# ESP32-S3 register map
Vendor: ESPRESSIF SYSTEMS (SHANGHAI) CO., LTD.; Series: ESP32 S-Series; File version: 22
CPU: Xtensa LX7 r0p0, little endian, no MPU, FPU, 0 interrupt priority bits
Address unit: 32 bits
Registers are 32-bit, read-write, reset 0x0 unless marked. A register's access mark holds for its fields unless they carry their own. Offsets are from the block's base; [hi:lo] are bit positions; {n}, {i} and the like mark numbered series.

## RTC_CNTL — Real-Time Clock Control
Base 0x60008000
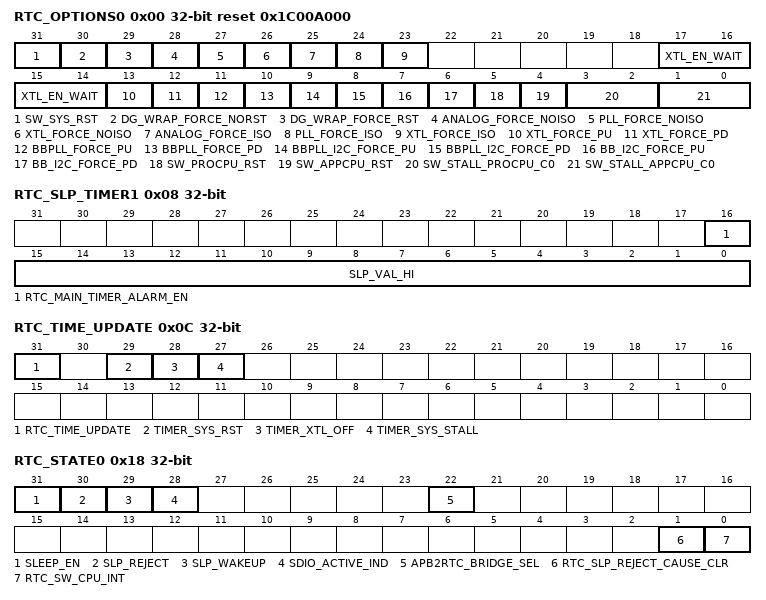
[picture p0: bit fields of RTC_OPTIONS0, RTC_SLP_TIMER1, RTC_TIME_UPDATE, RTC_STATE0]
0x00 RTC_OPTIONS0 access per field reset 0x1C00A000 — RTC common configure register
  [31] SW_SYS_RST wo — SW system reset
  [30] DG_WRAP_FORCE_NORST rw — digital core force no reset in deep sleep
  [29] DG_WRAP_FORCE_RST rw — digital wrap force reset in deep sleep
  [28] ANALOG_FORCE_NOISO rw — No public
  [27] PLL_FORCE_NOISO rw — No public
  [26] XTL_FORCE_NOISO rw — No public
  [25] ANALOG_FORCE_ISO rw — No public
  [24] PLL_FORCE_ISO rw — No public
  [23] XTL_FORCE_ISO rw — No public
  [17:14] XTL_EN_WAIT rw — wait bias_sleep and current source wakeup
  [13] XTL_FORCE_PU rw — crystall force power up
  [12] XTL_FORCE_PD rw — crystall force power down
  [11] BBPLL_FORCE_PU rw — BB_PLL force power up
  [10] BBPLL_FORCE_PD rw — BB_PLL force power down
  [9] BBPLL_I2C_FORCE_PU rw — BB_PLL_I2C force power up
  [8] BBPLL_I2C_FORCE_PD rw — BB_PLL _I2C force power down
  [7] BB_I2C_FORCE_PU rw — BB_I2C force power up
  [6] BB_I2C_FORCE_PD rw — BB_I2C force power down
  [5] SW_PROCPU_RST wo — PRO CPU SW reset
  [4] SW_APPCPU_RST wo — APP CPU SW reset
  [3:2] SW_STALL_PROCPU_C0 rw — {reg_sw_stall_procpu_c1[5:0], reg_sw_stall_procpu_c0[1:0]} == 0x86 will stall PRO CPU
  [1:0] SW_STALL_APPCPU_C0 rw — {reg_sw_stall_appcpu_c1[5:0], reg_sw_stall_appcpu_c0[1:0]} == 0x86 will stall APP CPU
0x04 RTC_SLP_TIMER0 — configure min sleep time
  [31:0] SLP_VAL_LO — RTC sleep timer low 32 bits
0x08 RTC_SLP_TIMER1 access per field — configure sleep time hi
  [16] RTC_MAIN_TIMER_ALARM_EN wo — timer alarm enable bit
  [15:0] SLP_VAL_HI rw — RTC sleep timer high 16 bits
0x0C RTC_TIME_UPDATE access per field — update rtc main timer
  [31] RTC_TIME_UPDATE wo — Set 1: to update register with RTC timer
  [29] TIMER_SYS_RST rw — enable to record system reset time
  [28] TIMER_XTL_OFF rw — Enable to record 40M XTAL OFF time
  [27] TIMER_SYS_STALL rw — Enable to record system stall time
0x10 RTC_TIME_LOW0 ro — read rtc_main timer low bits
  [31:0] RTC_TIMER_VALUE0_LOW — RTC timer low 32 bits
0x14 RTC_TIME_HIGH0 ro — read rtc_main timer high bits
  [15:0] RTC_TIMER_VALUE0_HIGH — RTC timer high 16 bits
0x18 RTC_STATE0 access per field — configure chip sleep
  [31] SLEEP_EN rw — sleep enable bit
  [30] SLP_REJECT rw — leep reject bit
  [29] SLP_WAKEUP rw — leep wakeup bit
  [28] SDIO_ACTIVE_IND ro — SDIO active indication
  [22] APB2RTC_BRIDGE_SEL rw — 1: APB to RTC using bridge, 0: APB to RTC using sync
  [1] RTC_SLP_REJECT_CAUSE_CLR wo — clear rtc sleep reject cause
  [0] RTC_SW_CPU_INT wo — rtc software interrupt to main cpu
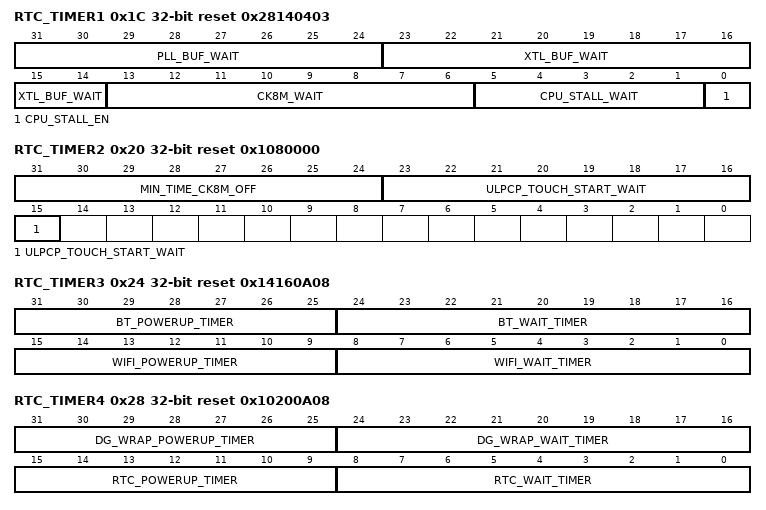
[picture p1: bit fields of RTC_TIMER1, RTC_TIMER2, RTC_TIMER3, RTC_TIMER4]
0x1C RTC_TIMER1 reset 0x28140403 — rtc state wait time
  [31:24] PLL_BUF_WAIT — PLL wait cycles in slow_clk_rtc
  [23:14] XTL_BUF_WAIT — XTAL wait cycles in slow_clk_rtc
  [13:6] CK8M_WAIT — CK8M wait cycles in slow_clk_rtc
  [5:1] CPU_STALL_WAIT — CPU stall wait cycles in fast_clk_rtc
  [0] CPU_STALL_EN — CPU stall enable bit
0x20 RTC_TIMER2 reset 0x1080000 — rtc monitor state delay time
  [31:24] MIN_TIME_CK8M_OFF — minimal cycles in slow_clk_rtc for CK8M in power down state
  [23:15] ULPCP_TOUCH_START_WAIT — wait cycles in slow_clk_rtc before ULP-coprocessor / touch controller start to work
0x24 RTC_TIMER3 reset 0x14160A08 — No public
  [31:25] BT_POWERUP_TIMER — No public
  [24:16] BT_WAIT_TIMER — No public
  [15:9] WIFI_POWERUP_TIMER — No public
  [8:0] WIFI_WAIT_TIMER — No public
0x28 RTC_TIMER4 reset 0x10200A08 — No public
  [31:25] DG_WRAP_POWERUP_TIMER — No public
  [24:16] DG_WRAP_WAIT_TIMER — No public
  [15:9] RTC_POWERUP_TIMER — No public
  [8:0] RTC_WAIT_TIMER — No public
0x2C RTC_TIMER5 reset 0x8000 — configure min sleep time
  [15:8] MIN_SLP_VAL — minimal sleep cycles in slow_clk_rtc
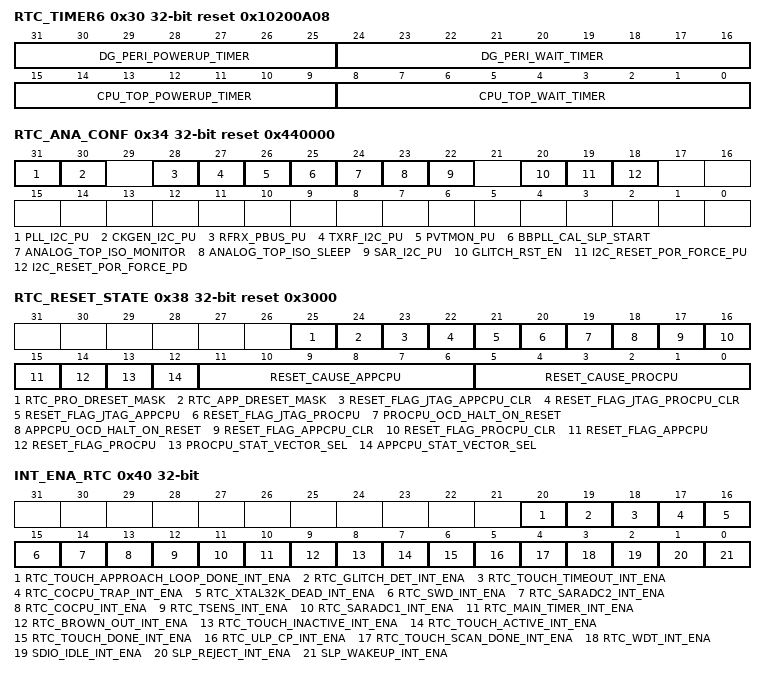
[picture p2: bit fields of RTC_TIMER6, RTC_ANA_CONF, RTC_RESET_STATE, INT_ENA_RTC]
0x30 RTC_TIMER6 reset 0x10200A08 — No public
  [31:25] DG_PERI_POWERUP_TIMER — No public
  [24:16] DG_PERI_WAIT_TIMER — No public
  [15:9] CPU_TOP_POWERUP_TIMER — No public
  [8:0] CPU_TOP_WAIT_TIMER — No public
0x34 RTC_ANA_CONF reset 0x440000 — analog configure register
  [31] PLL_I2C_PU — power on pll i2c
  [30] CKGEN_I2C_PU — 1: CKGEN_I2C power up, otherwise power down
  [28] RFRX_PBUS_PU — 1: RFRX_PBUS power up, otherwise power down
  [27] TXRF_I2C_PU — 1: TXRF_I2C power up, otherwise power down
  [26] PVTMON_PU — 1: PVTMON power up, otherwise power down
  [25] BBPLL_CAL_SLP_START — start BBPLL calibration during sleep
  [24] ANALOG_TOP_ISO_MONITOR — PLLA force power up
  [23] ANALOG_TOP_ISO_SLEEP — PLLA force power down
  [22] SAR_I2C_PU — PLLA force power up
  [20] GLITCH_RST_EN — enable clk glitch
  [19] I2C_RESET_POR_FORCE_PU — force on I2C_RESET_POR
  [18] I2C_RESET_POR_FORCE_PD — force down I2C_RESET_POR
0x38 RTC_RESET_STATE access per field reset 0x3000 — get reset state
  [25] RTC_PRO_DRESET_MASK rw — bypass cpu0 dreset
  [24] RTC_APP_DRESET_MASK rw — bypass cpu1 dreset
  [23] RESET_FLAG_JTAG_APPCPU_CLR wo — clear jtag reset flag
  [22] RESET_FLAG_JTAG_PROCPU_CLR wo — clear jtag reset flag
  [21] RESET_FLAG_JTAG_APPCPU ro — jtag reset flag
  [20] RESET_FLAG_JTAG_PROCPU ro — jtag reset flag
  [19] PROCPU_OCD_HALT_ON_RESET rw
  [18] APPCPU_OCD_HALT_ON_RESET rw
  [17] RESET_FLAG_APPCPU_CLR wo — clear APP CPU reset flag
  [16] RESET_FLAG_PROCPU_CLR wo — clear PRO CPU reset_flag
  [15] RESET_FLAG_APPCPU ro — APP CPU reset flag
  [14] RESET_FLAG_PROCPU ro — PRO CPU reset_flag
  [13] PROCPU_STAT_VECTOR_SEL rw — PRO CPU state vector sel
  [12] APPCPU_STAT_VECTOR_SEL rw — APP CPU state vector sel
  [11:6] RESET_CAUSE_APPCPU ro — reset cause of APP CPU
  [5:0] RESET_CAUSE_PROCPU ro — reset cause of PRO CPU
0x3C RTC_WAKEUP_STATE reset 0x60000 — configure wakeup state
  [31:15] RTC_WAKEUP_ENA — wakeup enable bitmap
0x40 INT_ENA_RTC — configure rtc interrupt register
  [20] RTC_TOUCH_APPROACH_LOOP_DONE_INT_ENA — touch approach mode loop interrupt
  [19] RTC_GLITCH_DET_INT_ENA — enbale gitch det interrupt
  [18] RTC_TOUCH_TIMEOUT_INT_ENA — enable touch timeout interrupt
  [17] RTC_COCPU_TRAP_INT_ENA — enable cocpu trap interrupt
  [16] RTC_XTAL32K_DEAD_INT_ENA — enable xtal32k_dead interrupt
  [15] RTC_SWD_INT_ENA — enable super watch dog interrupt
  [14] RTC_SARADC2_INT_ENA — enable saradc2 interrupt
  [13] RTC_COCPU_INT_ENA — enable riscV cocpu interrupt
  [12] RTC_TSENS_INT_ENA — enable tsens interrupt
  [11] RTC_SARADC1_INT_ENA — enable saradc1 interrupt
  [10] RTC_MAIN_TIMER_INT_ENA — enable RTC main timer interrupt
  [9] RTC_BROWN_OUT_INT_ENA — enable brown out interrupt
  [8] RTC_TOUCH_INACTIVE_INT_ENA — enable touch inactive interrupt
  [7] RTC_TOUCH_ACTIVE_INT_ENA — enable touch active interrupt
  [6] RTC_TOUCH_DONE_INT_ENA — enable touch done interrupt
  [5] RTC_ULP_CP_INT_ENA — enable ULP-coprocessor interrupt
  [4] RTC_TOUCH_SCAN_DONE_INT_ENA — enable touch scan done interrupt
  [3] RTC_WDT_INT_ENA — enable RTC WDT interrupt
  [2] SDIO_IDLE_INT_ENA — enable SDIO idle interrupt
  [1] SLP_REJECT_INT_ENA — enable sleep reject interrupt
  [0] SLP_WAKEUP_INT_ENA — enable sleep wakeup interrupt
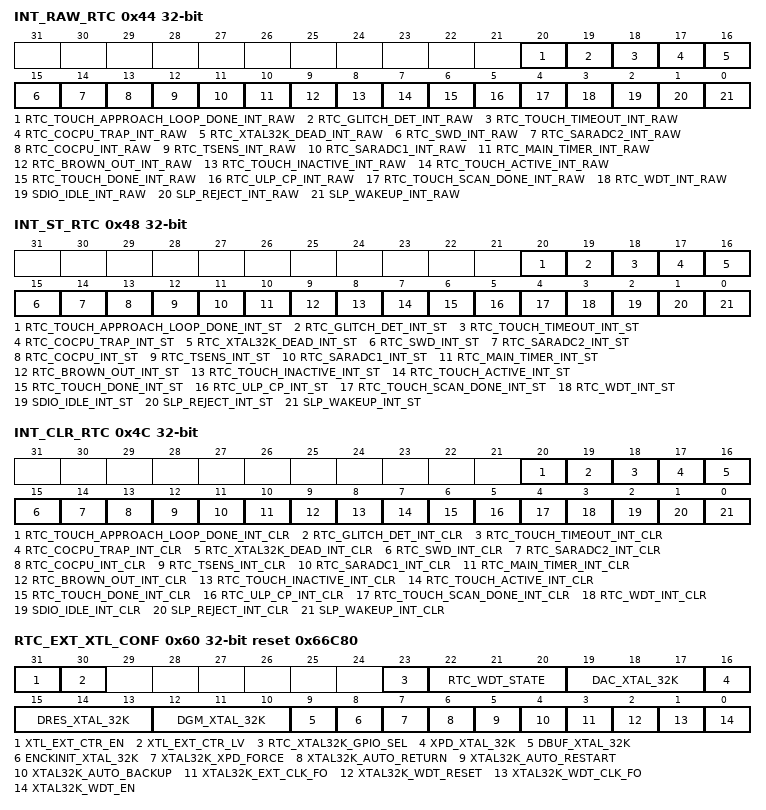
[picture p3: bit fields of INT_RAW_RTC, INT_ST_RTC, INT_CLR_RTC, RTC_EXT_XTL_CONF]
0x44 INT_RAW_RTC access per field — rtc interrupt register
  [20] RTC_TOUCH_APPROACH_LOOP_DONE_INT_RAW rw — touch approach mode loop interrupt raw
  [19] RTC_GLITCH_DET_INT_RAW ro — glitch_det_interrupt_raw
  [18] RTC_TOUCH_TIMEOUT_INT_RAW ro — touch timeout interrupt raw
  [17] RTC_COCPU_TRAP_INT_RAW ro — cocpu trap interrupt raw
  [16] RTC_XTAL32K_DEAD_INT_RAW ro — xtal32k dead detection interrupt raw
  [15] RTC_SWD_INT_RAW ro — super watch dog interrupt raw
  [14] RTC_SARADC2_INT_RAW ro — saradc2 interrupt raw
  [13] RTC_COCPU_INT_RAW ro — riscV cocpu interrupt raw
  [12] RTC_TSENS_INT_RAW ro — tsens interrupt raw
  [11] RTC_SARADC1_INT_RAW ro — saradc1 interrupt raw
  [10] RTC_MAIN_TIMER_INT_RAW ro — RTC main timer interrupt raw
  [9] RTC_BROWN_OUT_INT_RAW ro — brown out interrupt raw
  [8] RTC_TOUCH_INACTIVE_INT_RAW ro — touch inactive interrupt raw
  [7] RTC_TOUCH_ACTIVE_INT_RAW ro — touch active interrupt raw
  [6] RTC_TOUCH_DONE_INT_RAW ro — touch interrupt raw
  [5] RTC_ULP_CP_INT_RAW ro — ULP-coprocessor interrupt raw
  [4] RTC_TOUCH_SCAN_DONE_INT_RAW ro — enable touch scan done interrupt raw
  [3] RTC_WDT_INT_RAW ro — RTC WDT interrupt raw
  [2] SDIO_IDLE_INT_RAW ro — SDIO idle interrupt raw
  [1] SLP_REJECT_INT_RAW ro — sleep reject interrupt raw
  [0] SLP_WAKEUP_INT_RAW ro — sleep wakeup interrupt raw
0x48 INT_ST_RTC ro — rtc interrupt register
  [20] RTC_TOUCH_APPROACH_LOOP_DONE_INT_ST — touch approach mode loop interrupt state
  [19] RTC_GLITCH_DET_INT_ST — glitch_det_interrupt state
  [18] RTC_TOUCH_TIMEOUT_INT_ST — Touch timeout interrupt state
  [17] RTC_COCPU_TRAP_INT_ST — cocpu trap interrupt state
  [16] RTC_XTAL32K_DEAD_INT_ST — xtal32k dead detection interrupt state
  [15] RTC_SWD_INT_ST — super watch dog interrupt state
  [14] RTC_SARADC2_INT_ST — saradc2 interrupt state
  [13] RTC_COCPU_INT_ST — riscV cocpu interrupt state
  [12] RTC_TSENS_INT_ST — tsens interrupt state
  [11] RTC_SARADC1_INT_ST — saradc1 interrupt state
  [10] RTC_MAIN_TIMER_INT_ST — RTC main timer interrupt state
  [9] RTC_BROWN_OUT_INT_ST — brown out interrupt state
  [8] RTC_TOUCH_INACTIVE_INT_ST — touch inactive interrupt state
  [7] RTC_TOUCH_ACTIVE_INT_ST — touch active interrupt state
  [6] RTC_TOUCH_DONE_INT_ST — touch done interrupt state
  [5] RTC_ULP_CP_INT_ST — ULP-coprocessor interrupt state
  [4] RTC_TOUCH_SCAN_DONE_INT_ST — enable touch scan done interrupt raw
  [3] RTC_WDT_INT_ST — RTC WDT interrupt state
  [2] SDIO_IDLE_INT_ST — SDIO idle interrupt state
  [1] SLP_REJECT_INT_ST — sleep reject interrupt state
  [0] SLP_WAKEUP_INT_ST — sleep wakeup interrupt state
0x4C INT_CLR_RTC wo — rtc interrupt register
  [20] RTC_TOUCH_APPROACH_LOOP_DONE_INT_CLR — cleartouch approach mode loop interrupt state
  [19] RTC_GLITCH_DET_INT_CLR — Clear glitch det interrupt state
  [18] RTC_TOUCH_TIMEOUT_INT_CLR — Clear touch timeout interrupt state
  [17] RTC_COCPU_TRAP_INT_CLR — Clear cocpu trap interrupt state
  [16] RTC_XTAL32K_DEAD_INT_CLR — Clear RTC WDT interrupt state
  [15] RTC_SWD_INT_CLR — Clear super watch dog interrupt state
  [14] RTC_SARADC2_INT_CLR — Clear saradc2 interrupt state
  [13] RTC_COCPU_INT_CLR — Clear riscV cocpu interrupt state
  [12] RTC_TSENS_INT_CLR — Clear tsens interrupt state
  [11] RTC_SARADC1_INT_CLR — Clear saradc1 interrupt state
  [10] RTC_MAIN_TIMER_INT_CLR — Clear RTC main timer interrupt state
  [9] RTC_BROWN_OUT_INT_CLR — Clear brown out interrupt state
  [8] RTC_TOUCH_INACTIVE_INT_CLR — Clear touch inactive interrupt state
  [7] RTC_TOUCH_ACTIVE_INT_CLR — Clear touch active interrupt state
  [6] RTC_TOUCH_DONE_INT_CLR — Clear touch done interrupt state
  [5] RTC_ULP_CP_INT_CLR — Clear ULP-coprocessor interrupt state
  [4] RTC_TOUCH_SCAN_DONE_INT_CLR — clear touch scan done interrupt raw
  [3] RTC_WDT_INT_CLR — Clear RTC WDT interrupt state
  [2] SDIO_IDLE_INT_CLR — Clear SDIO idle interrupt state
  [1] SLP_REJECT_INT_CLR — Clear sleep reject interrupt state
  [0] SLP_WAKEUP_INT_CLR — Clear sleep wakeup interrupt state
{0x50+4i} RTC_STORE{i} (i=0..3) — Reserved register
  [31:0] RTC_SCRATCH{i}
0x60 RTC_EXT_XTL_CONF access per field reset 0x66C80 — Reserved register
  [31] XTL_EXT_CTR_EN rw — Reserved register
  [30] XTL_EXT_CTR_LV rw — 0: power down XTAL at high level, 1: power down XTAL at low level
  [23] RTC_XTAL32K_GPIO_SEL rw — XTAL_32K sel. 0: external XTAL_32K, 1: CLK from RTC pad X32P_C
  [22:20] RTC_WDT_STATE ro — state of 32k_wdt
  [19:17] DAC_XTAL_32K rw
  [16] XPD_XTAL_32K rw
  [15:13] DRES_XTAL_32K rw
  [12:10] DGM_XTAL_32K rw — xtal_32k gm control
  [9] DBUF_XTAL_32K rw — 0: single-end buffer 1: differential buffer
  [8] ENCKINIT_XTAL_32K rw — apply an internal clock to help xtal 32k to start
  [7] XTAL32K_XPD_FORCE rw — Xtal 32k xpd control by sw or fsm
  [6] XTAL32K_AUTO_RETURN rw — xtal 32k switch back xtal when xtal is restarted
  [5] XTAL32K_AUTO_RESTART rw — xtal 32k restart xtal when xtal is dead
  [4] XTAL32K_AUTO_BACKUP rw — xtal 32k switch to back up clock when xtal is dead
  [3] XTAL32K_EXT_CLK_FO rw — xtal 32k external xtal clock force on
  [2] XTAL32K_WDT_RESET rw — xtal 32k watch dog sw reset
  [1] XTAL32K_WDT_CLK_FO rw — xtal 32k watch dog clock force on
  [0] XTAL32K_WDT_EN rw — xtal 32k watch dog enable
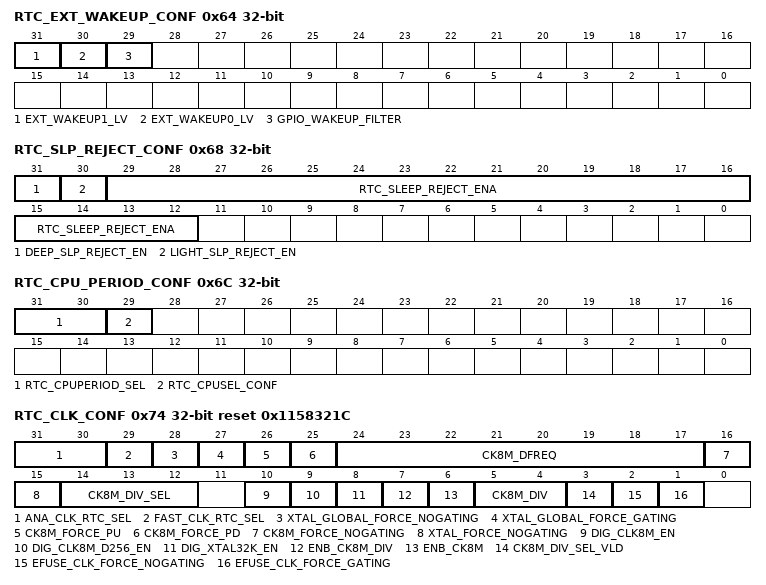
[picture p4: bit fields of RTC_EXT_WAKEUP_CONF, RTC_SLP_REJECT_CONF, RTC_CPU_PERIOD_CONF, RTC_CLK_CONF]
0x64 RTC_EXT_WAKEUP_CONF — ext wakeup configure
  [31] EXT_WAKEUP1_LV — 0: external wakeup at low level, 1: external wakeup at high level
  [30] EXT_WAKEUP0_LV — 0: external wakeup at low level, 1: external wakeup at high level
  [29] GPIO_WAKEUP_FILTER — enable filter for gpio wakeup event
0x68 RTC_SLP_REJECT_CONF — reject sleep register
  [31] DEEP_SLP_REJECT_EN — enable reject for deep sleep
  [30] LIGHT_SLP_REJECT_EN — enable reject for light sleep
  [29:12] RTC_SLEEP_REJECT_ENA — sleep reject enable
0x6C RTC_CPU_PERIOD_CONF — conigure cpu freq
  [31:30] RTC_CPUPERIOD_SEL — conigure cpu freq
  [29] RTC_CPUSEL_CONF — CPU sel option
0x70 RTC_SDIO_ACT_CONF — No public
  [31:22] SDIO_ACT_DNUM
0x74 RTC_CLK_CONF reset 0x1158321C — configure clock register
  [31:30] ANA_CLK_RTC_SEL — select slow clock
  [29] FAST_CLK_RTC_SEL — fast_clk_rtc sel. 0: XTAL div 4, 1: CK8M
  [28] XTAL_GLOBAL_FORCE_NOGATING — force global xtal no gating
  [27] XTAL_GLOBAL_FORCE_GATING — force global xtal gating
  [26] CK8M_FORCE_PU — CK8M force power up
  [25] CK8M_FORCE_PD — CK8M force power down
  [24:17] CK8M_DFREQ
  [16] CK8M_FORCE_NOGATING — CK8M force no gating during sleep
  [15] XTAL_FORCE_NOGATING — XTAL force no gating during sleep
  [14:12] CK8M_DIV_SEL — divider = reg_ck8m_div_sel + 1
  [10] DIG_CLK8M_EN — enable CK8M for digital core (no relationship with RTC core)
  [9] DIG_CLK8M_D256_EN — enable CK8M_D256_OUT for digital core (no relationship with RTC core)
  [8] DIG_XTAL32K_EN — enable CK_XTAL_32K for digital core (no relationship with RTC core)
  [7] ENB_CK8M_DIV — 1: CK8M_D256_OUT is actually CK8M, 0: CK8M_D256_OUT is CK8M divided by 256
  [6] ENB_CK8M — disable CK8M and CK8M_D256_OUT
  [5:4] CK8M_DIV — CK8M_D256_OUT divider. 00: div128, 01: div256, 10: div512, 11: div1024.
  [3] CK8M_DIV_SEL_VLD — used to sync reg_ck8m_div_sel bus. Clear vld before set reg_ck8m_div_sel, then set vld to actually switch the clk
  [2] EFUSE_CLK_FORCE_NOGATING — force efuse clk nogating
  [1] EFUSE_CLK_FORCE_GATING — force efuse clk gating
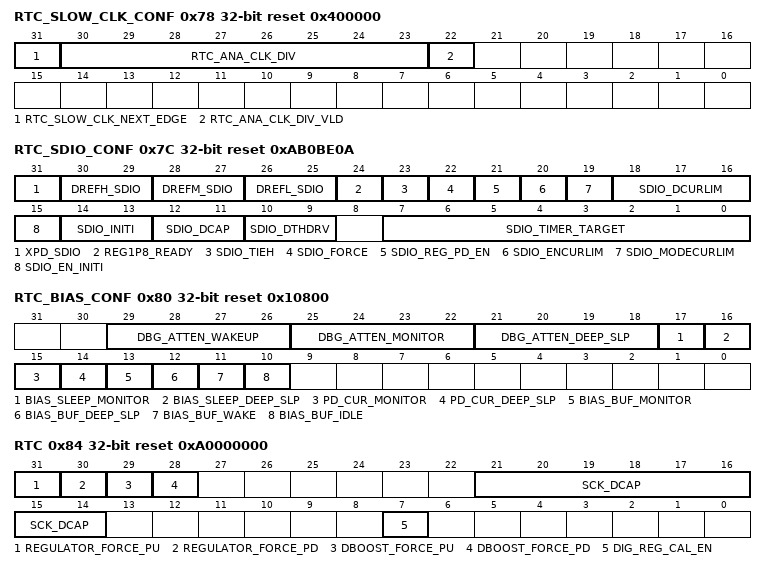
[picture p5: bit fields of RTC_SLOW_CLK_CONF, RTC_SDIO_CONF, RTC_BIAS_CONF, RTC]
0x78 RTC_SLOW_CLK_CONF reset 0x400000 — configure slow clk
  [31] RTC_SLOW_CLK_NEXT_EDGE — No public
  [30:23] RTC_ANA_CLK_DIV — rtc clk div
  [22] RTC_ANA_CLK_DIV_VLD — used to sync div bus. clear vld before set reg_rtc_ana_clk_div, then set vld to actually switch the clk
0x7C RTC_SDIO_CONF access per field reset 0xAB0BE0A — configure flash power
  [31] XPD_SDIO rw — power on flash regulator
  [30:29] DREFH_SDIO rw — SW option for DREFH_SDIO. Only active when reg_sdio_force = 1
  [28:27] DREFM_SDIO rw — SW option for DREFM_SDIO. Only active when reg_sdio_force = 1
  [26:25] DREFL_SDIO rw — SW option for DREFL_SDIO. Only active when reg_sdio_force = 1
  [24] REG1P8_READY ro — read only register for REG1P8_READY
  [23] SDIO_TIEH rw — SW option for SDIO_TIEH. Only active when reg_sdio_force = 1
  [22] SDIO_FORCE rw — 1: use SW option to control SDIO_REG, 0: use state machine
  [21] SDIO_REG_PD_EN rw — power down SDIO_REG in sleep. Only active when reg_sdio_force = 0
  [20] SDIO_ENCURLIM rw — enable current limit
  [19] SDIO_MODECURLIM rw — select current limit mode
  [18:16] SDIO_DCURLIM rw — tune current limit threshold when tieh = 0. About 800mA/(8+d)
  [15] SDIO_EN_INITI rw — 0 to set init[1:0]=0
  [14:13] SDIO_INITI rw — add resistor from ldo output to ground. 0: no res, 1: 6k,2:4k,3:2k
  [12:11] SDIO_DCAP rw — ability to prevent LDO from overshoot
  [10:9] SDIO_DTHDRV rw — Tieh = 1 mode drive ability. Initially set to 0 to limit charge current, set to 3 after several us.
  [7:0] SDIO_TIMER_TARGET rw — timer count to apply reg_sdio_dcap after sdio power on
0x80 RTC_BIAS_CONF reset 0x10800 — No public
  [29:26] DBG_ATTEN_WAKEUP — No public
  [25:22] DBG_ATTEN_MONITOR — DBG_ATTEN when rtc in monitor state
  [21:18] DBG_ATTEN_DEEP_SLP — DBG_ATTEN when rtc in sleep state
  [17] BIAS_SLEEP_MONITOR — bias_sleep when rtc in monitor state
  [16] BIAS_SLEEP_DEEP_SLP — bias_sleep when rtc in sleep_state
  [15] PD_CUR_MONITOR — xpd cur when rtc in monitor state
  [14] PD_CUR_DEEP_SLP — xpd cur when rtc in sleep_state
  [13] BIAS_BUF_MONITOR — No public
  [12] BIAS_BUF_DEEP_SLP — No public
  [11] BIAS_BUF_WAKE — No public
  [10] BIAS_BUF_IDLE — No public
0x84 RTC reset 0xA0000000 — configure rtc regulator
  [31] REGULATOR_FORCE_PU — RTC_REG force power on (for RTC_REG power down means decrease the voltage to 0.8v or lower )
  [30] REGULATOR_FORCE_PD — RTC_REG force power down (for RTC_REG power down means decrease the voltage to 0.8v or lower )
  [29] DBOOST_FORCE_PU — RTC_DBOOST force power up
  [28] DBOOST_FORCE_PD — RTC_DBOOST force power down
  [21:14] SCK_DCAP
  [7] DIG_REG_CAL_EN — enable dig regulator cali
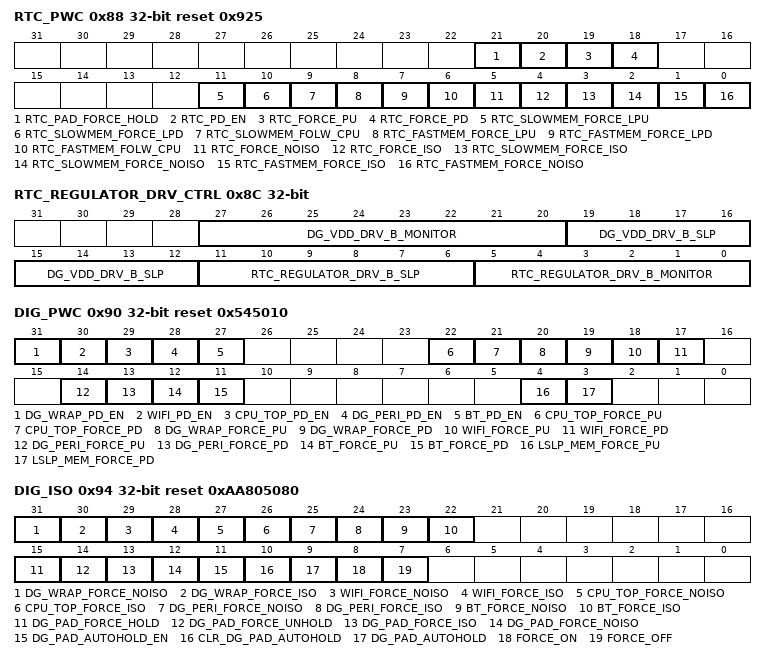
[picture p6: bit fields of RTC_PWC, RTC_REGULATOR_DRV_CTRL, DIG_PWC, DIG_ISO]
0x88 RTC_PWC reset 0x925 — configure rtc power
  [21] RTC_PAD_FORCE_HOLD
  [20] RTC_PD_EN — enable power down rtc_peri in sleep
  [19] RTC_FORCE_PU — rtc_peri force power up
  [18] RTC_FORCE_PD — rtc_peri force power down
  [11] RTC_SLOWMEM_FORCE_LPU — RTC memory force no PD
  [10] RTC_SLOWMEM_FORCE_LPD — RTC memory force PD
  [9] RTC_SLOWMEM_FOLW_CPU — 1: RTC memory PD following CPU, 0: RTC memory PD following RTC state machine
  [8] RTC_FASTMEM_FORCE_LPU — Fast RTC memory force no PD
  [7] RTC_FASTMEM_FORCE_LPD — Fast RTC memory force PD
  [6] RTC_FASTMEM_FOLW_CPU — 1: Fast RTC memory PD following CPU, 0: fast RTC memory PD following RTC state machine
  [5] RTC_FORCE_NOISO — rtc_peri force no ISO
  [4] RTC_FORCE_ISO — rtc_peri force ISO
  [3] RTC_SLOWMEM_FORCE_ISO — RTC memory force ISO
  [2] RTC_SLOWMEM_FORCE_NOISO — RTC memory force no ISO
  [1] RTC_FASTMEM_FORCE_ISO — Fast RTC memory force ISO
  [0] RTC_FASTMEM_FORCE_NOISO — Fast RTC memory force no ISO
0x8C RTC_REGULATOR_DRV_CTRL — No public
  [27:20] DG_VDD_DRV_B_MONITOR — No public
  [19:12] DG_VDD_DRV_B_SLP — No public
  [11:6] RTC_REGULATOR_DRV_B_SLP — No public
  [5:0] RTC_REGULATOR_DRV_B_MONITOR — No public
0x90 DIG_PWC reset 0x545010 — configure digital power
  [31] DG_WRAP_PD_EN — enable power down all digital logic
  [30] WIFI_PD_EN — enable power down wifi in sleep
  [29] CPU_TOP_PD_EN — enable power down internal SRAM 4 in sleep
  [28] DG_PERI_PD_EN — enable power down internal SRAM 3 in sleep
  [27] BT_PD_EN — enable power down internal SRAM 2 in sleep
  [22] CPU_TOP_FORCE_PU — digital dcdc force power up
  [21] CPU_TOP_FORCE_PD — digital dcdc force power down
  [20] DG_WRAP_FORCE_PU — digital core force power up
  [19] DG_WRAP_FORCE_PD — digital core force power down
  [18] WIFI_FORCE_PU — wifi force power up
  [17] WIFI_FORCE_PD — wifi force power down
  [14] DG_PERI_FORCE_PU — internal SRAM 3 force power up
  [13] DG_PERI_FORCE_PD — internal SRAM 3 force power down
  [12] BT_FORCE_PU — internal SRAM 2 force power up
  [11] BT_FORCE_PD — internal SRAM 2 force power down
  [4] LSLP_MEM_FORCE_PU — memories in digital core force no PD in sleep
  [3] LSLP_MEM_FORCE_PD — memories in digital core force PD in sleep
0x94 DIG_ISO access per field reset 0xAA805080 — congigure digital power isolation
  [31] DG_WRAP_FORCE_NOISO rw — digita core force no ISO
  [30] DG_WRAP_FORCE_ISO rw — digital core force ISO
  [29] WIFI_FORCE_NOISO rw
  [28] WIFI_FORCE_ISO rw
  [27] CPU_TOP_FORCE_NOISO rw — internal SRAM 4 force no ISO
  [26] CPU_TOP_FORCE_ISO rw — internal SRAM 4 force ISO
  [25] DG_PERI_FORCE_NOISO rw — internal SRAM 3 force no ISO
  [24] DG_PERI_FORCE_ISO rw — internal SRAM 3 force ISO
  [23] BT_FORCE_NOISO rw — internal SRAM 2 force no ISO
  [22] BT_FORCE_ISO rw — internal SRAM 2 force ISO
  [15] DG_PAD_FORCE_HOLD rw — digital pad force hold
  [14] DG_PAD_FORCE_UNHOLD rw — digital pad force un-hold
  [13] DG_PAD_FORCE_ISO rw — digital pad force ISO
  [12] DG_PAD_FORCE_NOISO rw — digital pad force no ISO
  [11] DG_PAD_AUTOHOLD_EN rw — digital pad enable auto-hold
  [10] CLR_DG_PAD_AUTOHOLD wo — wtite only register to clear digital pad auto-hold
  [9] DG_PAD_AUTOHOLD ro — read only register to indicate digital pad auto-hold status
  [8] FORCE_ON rw — No public
  [7] FORCE_OFF rw — No public
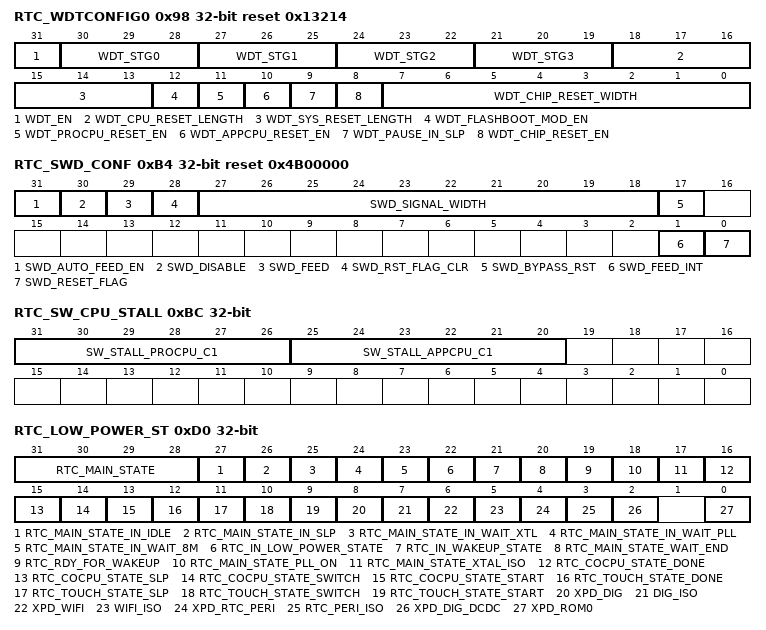
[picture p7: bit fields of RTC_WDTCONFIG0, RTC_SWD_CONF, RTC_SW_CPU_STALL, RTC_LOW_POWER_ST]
0x98 RTC_WDTCONFIG0 reset 0x13214 — configure rtc watch dog
  [31] WDT_EN — enable rtc watch dog
  [30-3n:28-3n] WDT_STG{n} (n=0..3) — 1: interrupt stage en 2: CPU reset stage en 3: system reset stage en 4: RTC reset stage en
  [18:16] WDT_CPU_RESET_LENGTH — CPU reset counter length
  [15:13] WDT_SYS_RESET_LENGTH — system reset counter length
  [12] WDT_FLASHBOOT_MOD_EN — enable WDT in flash boot
  [11] WDT_PROCPU_RESET_EN — enable WDT reset PRO CPU
  [10] WDT_APPCPU_RESET_EN — enable WDT reset APP CPU
  [9] WDT_PAUSE_IN_SLP — pause WDT in sleep
  [8] WDT_CHIP_RESET_EN — wdt reset whole chip enable
  [7:0] WDT_CHIP_RESET_WIDTH — chip reset siginal pulse width
0x9C RTC_WDTCONFIG1 reset 0x30D40 — stage0 hold time
  [31:0] WDT_STG0_HOLD
0xA0 RTC_WDTCONFIG2 reset 0x13880 — stage1 hold time
  [31:0] WDT_STG1_HOLD
0xA4 RTC_WDTCONFIG3 reset 0xFFF — stage2 hold time
  [31:0] WDT_STG2_HOLD
0xA8 RTC_WDTCONFIG4 reset 0xFFF — stage3 hold time
  [31:0] WDT_STG3_HOLD
0xAC RTC_WDTFEED wo
  [31] RTC_WDT_FEED
0xB0 RTC_WDTWPROTECT reset 0x50D83AA1 — configure rtc watch dog
  [31:0] WDT_WKEY — rtc watch dog key
0xB4 RTC_SWD_CONF access per field reset 0x4B00000 — congfigure super watch dog
  [31] SWD_AUTO_FEED_EN rw — automatically feed swd when int comes
  [30] SWD_DISABLE rw — disabel SWD
  [29] SWD_FEED wo — Sw feed swd
  [28] SWD_RST_FLAG_CLR wo — reset swd reset flag
  [27:18] SWD_SIGNAL_WIDTH rw — adjust signal width send to swd
  [17] SWD_BYPASS_RST rw — bypass super watch dog reset
  [1] SWD_FEED_INT ro — swd interrupt for feeding
  [0] SWD_RESET_FLAG ro
0xB8 RTC_SWD_WPROTECT reset 0x8F1D312A — super watch dog key
  [31:0] SWD_WKEY
0xBC RTC_SW_CPU_STALL — configure cpu stall by sw
  [31:26] SW_STALL_PROCPU_C1 — {reg_sw_stall_appcpu_c1[5:0], reg_sw_stall_appcpu_c0[1:0]} == 0x86 will stall APP CPU
  [25:20] SW_STALL_APPCPU_C1 — {reg_sw_stall_appcpu_c1[5:0], reg_sw_stall_appcpu_c0[1:0]} == 0x86 will stall APP CPU
{0xB0+4i} RTC_STORE{i} (i=4..7) — reserved register
  [31:0] RTC_SCRATCH{i}
0xD0 RTC_LOW_POWER_ST ro — reserved register
  [31:28] RTC_MAIN_STATE — rtc main state machine status
  [27] RTC_MAIN_STATE_IN_IDLE — rtc main state machine is in idle state
  [26] RTC_MAIN_STATE_IN_SLP — rtc main state machine is in sleep state
  [25] RTC_MAIN_STATE_IN_WAIT_XTL — rtc main state machine is in wait xtal state
  [24] RTC_MAIN_STATE_IN_WAIT_PLL — rtc main state machine is in wait pll state
  [23] RTC_MAIN_STATE_IN_WAIT_8M — rtc main state machine is in wait 8m state
  [22] RTC_IN_LOW_POWER_STATE — rtc main state machine is in the states of low power
  [21] RTC_IN_WAKEUP_STATE — rtc main state machine is in the states of wakeup process
  [20] RTC_MAIN_STATE_WAIT_END — rtc main state machine has been waited for some cycles
  [19] RTC_RDY_FOR_WAKEUP — rtc is ready to receive wake up trigger from wake up source
  [18] RTC_MAIN_STATE_PLL_ON — rtc main state machine is in states that pll should be running
  [17] RTC_MAIN_STATE_XTAL_ISO — no use any more
  [16] RTC_COCPU_STATE_DONE — ulp/cocpu is done
  [15] RTC_COCPU_STATE_SLP — ulp/cocpu is in sleep state
  [14] RTC_COCPU_STATE_SWITCH — ulp/cocpu is about to working. Switch rtc main state
  [13] RTC_COCPU_STATE_START — ulp/cocpu should start to work
  [12] RTC_TOUCH_STATE_DONE — touch is done
  [11] RTC_TOUCH_STATE_SLP — touch is in sleep state
  [10] RTC_TOUCH_STATE_SWITCH — touch is about to working. Switch rtc main state
  [9] RTC_TOUCH_STATE_START — touch should start to work
  [8] XPD_DIG — digital wrap power down
  [7] DIG_ISO — digital wrap iso
  [6] XPD_WIFI — wifi wrap power down
  [5] WIFI_ISO
  [4] XPD_RTC_PERI — rtc peripheral power down
  [3] RTC_PERI_ISO — rtc peripheral iso
  [2] XPD_DIG_DCDC — External DCDC power down
  [0] XPD_ROM0 — rom0 power down
0xD4 RTC_DIAG0 ro — No public
  [31:0] RTC_LOW_POWER_DIAG1
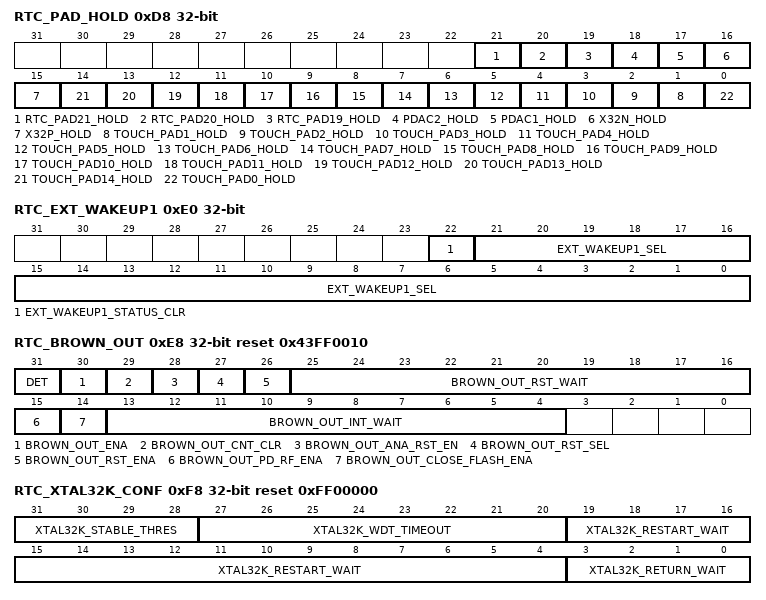
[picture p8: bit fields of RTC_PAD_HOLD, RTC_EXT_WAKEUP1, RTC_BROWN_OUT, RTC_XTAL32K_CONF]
0xD8 RTC_PAD_HOLD — rtc pad hold configure
  [21] RTC_PAD21_HOLD — hold rtc pad-21
  [20] RTC_PAD20_HOLD — hold rtc pad-20
  [19] RTC_PAD19_HOLD — hold rtc pad-19
  [18] PDAC2_HOLD — hold rtc pad-18
  [17] PDAC1_HOLD — hold rtc pad-17
  [16] X32N_HOLD — hold rtc pad-16
  [15] X32P_HOLD — hold rtc pad-15
  [n] TOUCH_PAD{n}_HOLD (n=1..14) — hold rtc pad-{n}
  [0] TOUCH_PAD0_HOLD — hold rtc pad0
0xDC DIG_PAD_HOLD — configure digtal pad hold
0xE0 RTC_EXT_WAKEUP1 access per field — configure ext1 wakeup
  [22] EXT_WAKEUP1_STATUS_CLR wo — clear ext wakeup1 status
  [21:0] EXT_WAKEUP1_SEL rw — Bitmap to select RTC pads for ext wakeup1
0xE4 RTC_EXT_WAKEUP1_STATUS ro — check ext wakeup1 status
  [21:0] EXT_WAKEUP1_STATUS
0xE8 RTC_BROWN_OUT access per field reset 0x43FF0010 — congfigure brownout
  [31] DET ro — get brown out detect
  [30] BROWN_OUT_ENA rw — enable brown out
  [29] BROWN_OUT_CNT_CLR wo — clear brown out counter
  [28] BROWN_OUT_ANA_RST_EN rw — enable brown out reset en
  [27] BROWN_OUT_RST_SEL rw — 1: 4-pos reset, 0: sys_reset
  [26] BROWN_OUT_RST_ENA rw — enable brown out reset
  [25:16] BROWN_OUT_RST_WAIT rw — brown out reset wait cycles
  [15] BROWN_OUT_PD_RF_ENA rw — enable power down RF when brown out happens
  [14] BROWN_OUT_CLOSE_FLASH_ENA rw — enable close flash when brown out happens
  [13:4] BROWN_OUT_INT_WAIT rw — brown out interrupt wait cycles
0xEC RTC_TIME_LOW1 ro — RTC timer low 32 bits
  [31:0] RTC_TIMER_VALUE1_LOW
0xF0 RTC_TIME_HIGH1 ro — RTC timer high 16 bits
  [15:0] RTC_TIMER_VALUE1_HIGH
0xF4 RTC_XTAL32K_CLK_FACTOR — xtal 32k watch dog backup clock factor
  [31:0] XTAL32K_CLK_FACTOR
0xF8 RTC_XTAL32K_CONF reset 0xFF00000 — configure xtal32k
  [31:28] XTAL32K_STABLE_THRES — if restarted xtal32k period is smaller than this, it is regarded as stable
  [27:20] XTAL32K_WDT_TIMEOUT — If no clock detected for this amount of time 32k is regarded as dead
  [19:4] XTAL32K_RESTART_WAIT — cycles to wait to repower on xtal 32k
  [3:0] XTAL32K_RETURN_WAIT — cycles to wait to return noral xtal 32k
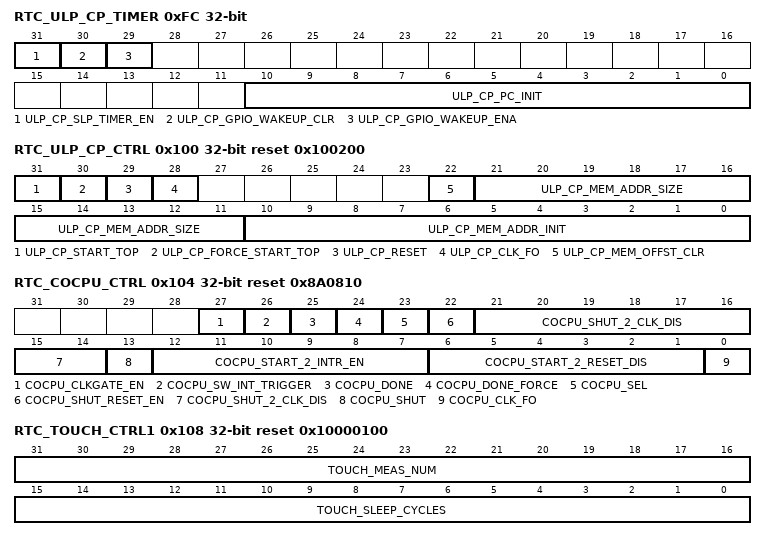
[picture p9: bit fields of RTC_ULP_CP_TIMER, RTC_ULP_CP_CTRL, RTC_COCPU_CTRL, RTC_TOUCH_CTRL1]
0xFC RTC_ULP_CP_TIMER access per field — configure ulp
  [31] ULP_CP_SLP_TIMER_EN rw — ULP-coprocessor timer enable bit
  [30] ULP_CP_GPIO_WAKEUP_CLR wo — ULP-coprocessor wakeup by GPIO state clear
  [29] ULP_CP_GPIO_WAKEUP_ENA rw — ULP-coprocessor wakeup by GPIO enable
  [10:0] ULP_CP_PC_INIT rw — ULP-coprocessor PC initial address
0x100 RTC_ULP_CP_CTRL access per field reset 0x100200 — configure ulp
  [31] ULP_CP_START_TOP rw — Write 1 to start ULP-coprocessor
  [30] ULP_CP_FORCE_START_TOP rw — 1: ULP-coprocessor is started by SW
  [29] ULP_CP_RESET rw — ulp coprocessor clk software reset
  [28] ULP_CP_CLK_FO rw — ulp coprocessor clk force on
  [22] ULP_CP_MEM_OFFST_CLR wo — No public
  [21:11] ULP_CP_MEM_ADDR_SIZE rw — No public
  [10:0] ULP_CP_MEM_ADDR_INIT rw — No public
0x104 RTC_COCPU_CTRL access per field reset 0x8A0810 — configure ulp-riscv
  [27] COCPU_CLKGATE_EN rw — open ulp-riscv clk gate
  [26] COCPU_SW_INT_TRIGGER wo — trigger cocpu register interrupt
  [25] COCPU_DONE rw — done signal used by riscv to control timer.
  [24] COCPU_DONE_FORCE rw — 1: select riscv done 0: select ulp done
  [23] COCPU_SEL rw — 1: old ULP 0: new riscV
  [22] COCPU_SHUT_RESET_EN rw — to reset cocpu
  [21:14] COCPU_SHUT_2_CLK_DIS rw — time from shut cocpu to disable clk
  [13] COCPU_SHUT rw — to shut cocpu
  [12:7] COCPU_START_2_INTR_EN rw — time from start cocpu to give start interrupt
  [6:1] COCPU_START_2_RESET_DIS rw — time from start cocpu to pull down reset
  [0] COCPU_CLK_FO rw — cocpu clk force on
0x108 RTC_TOUCH_CTRL1 reset 0x10000100 — configure touch controller
  [31:16] TOUCH_MEAS_NUM — the meas length (in 8MHz)
  [15:0] TOUCH_SLEEP_CYCLES — sleep cycles for timer
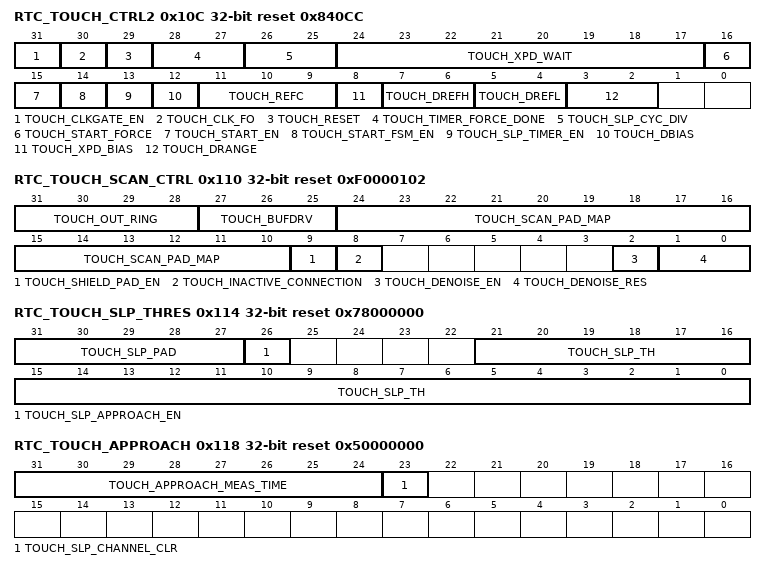
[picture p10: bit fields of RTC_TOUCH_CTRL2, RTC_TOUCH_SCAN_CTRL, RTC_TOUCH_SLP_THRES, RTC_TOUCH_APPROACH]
0x10C RTC_TOUCH_CTRL2 reset 0x840CC — configure touch controller
  [31] TOUCH_CLKGATE_EN — touch clock enable
  [30] TOUCH_CLK_FO — touch clock force on
  [29] TOUCH_RESET — reset upgrade touch
  [28:27] TOUCH_TIMER_FORCE_DONE — force touch timer done
  [26:25] TOUCH_SLP_CYC_DIV — when a touch pad is active sleep cycle could be divided by this number
  [24:17] TOUCH_XPD_WAIT — the waiting cycles (in 8MHz) between TOUCH_START and TOUCH_XPD
  [16] TOUCH_START_FORCE — 1: to start touch fsm by SW
  [15] TOUCH_START_EN — 1: start touch fsm
  [14] TOUCH_START_FSM_EN — 1: TOUCH_START & TOUCH_XPD is controlled by touch fsm
  [13] TOUCH_SLP_TIMER_EN — touch timer enable bit
  [12] TOUCH_DBIAS — 1:use self bias 0:use bandgap bias
  [11:9] TOUCH_REFC — TOUCH pad0 reference cap
  [8] TOUCH_XPD_BIAS
  [7:6] TOUCH_DREFH
  [5:4] TOUCH_DREFL
  [3:2] TOUCH_DRANGE
0x110 RTC_TOUCH_SCAN_CTRL reset 0xF0000102 — configure touch controller
  [31:28] TOUCH_OUT_RING — select out ring pad
  [27:25] TOUCH_BUFDRV — touch7 buffer driver strength
  [24:10] TOUCH_SCAN_PAD_MAP — touch scan mode pad enable map
  [9] TOUCH_SHIELD_PAD_EN — touch pad14 will be used as shield
  [8] TOUCH_INACTIVE_CONNECTION — inactive touch pads connect to 1: gnd 0: HighZ
  [2] TOUCH_DENOISE_EN — touch pad0 will be used to de-noise
  [1:0] TOUCH_DENOISE_RES — De-noise resolution: 12/10/8/4 bit
0x114 RTC_TOUCH_SLP_THRES reset 0x78000000 — configure touch controller
  [31:27] TOUCH_SLP_PAD — configure which pad as slp pad
  [26] TOUCH_SLP_APPROACH_EN — sleep pad approach function enable
  [21:0] TOUCH_SLP_TH — the threshold for sleep touch pad
0x118 RTC_TOUCH_APPROACH access per field reset 0x50000000 — configure touch controller
  [31:24] TOUCH_APPROACH_MEAS_TIME rw — approach pads total meas times
  [23] TOUCH_SLP_CHANNEL_CLR wo — clear touch slp channel
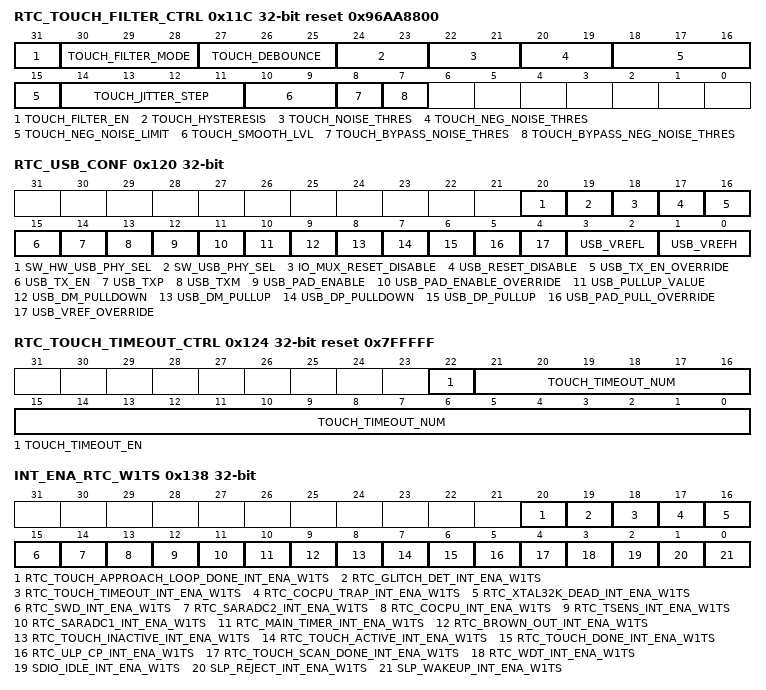
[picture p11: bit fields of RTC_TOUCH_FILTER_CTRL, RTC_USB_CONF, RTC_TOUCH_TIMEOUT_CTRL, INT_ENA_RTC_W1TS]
0x11C RTC_TOUCH_FILTER_CTRL reset 0x96AA8800 — configure touch controller
  [31] TOUCH_FILTER_EN — touch filter enable
  [30:28] TOUCH_FILTER_MODE — 0: IIR ? 1: IIR ? 2: IIR 1/8 3: Jitter
  [27:25] TOUCH_DEBOUNCE — debounce counter
  [24:23] TOUCH_HYSTERESIS — hysteresis
  [22:21] TOUCH_NOISE_THRES — noise thres
  [20:19] TOUCH_NEG_NOISE_THRES — neg noise thres
  [18:15] TOUCH_NEG_NOISE_LIMIT — negative threshold counter limit
  [14:11] TOUCH_JITTER_STEP
  [10:9] TOUCH_SMOOTH_LVL — smooth filter factor
  [8] TOUCH_BYPASS_NOISE_THRES — bypaas noise thres
  [7] TOUCH_BYPASS_NEG_NOISE_THRES — bypass neg noise thres
0x120 RTC_USB_CONF — usb configure
  [20] SW_HW_USB_PHY_SEL — reg_sw_hw_usb_phy_sel
  [19] SW_USB_PHY_SEL — reg_sw_usb_phy_sel
  [18] IO_MUX_RESET_DISABLE — reg_io_mux_reset_disable
  [17] USB_RESET_DISABLE — reg_usb_reset_disable
  [16] USB_TX_EN_OVERRIDE — reg_usb_tx_en_override
  [15] USB_TX_EN — reg_usb_tx_en
  [14] USB_TXP — reg_usb_txp
  [13] USB_TXM — reg_usb_txm
  [12] USB_PAD_ENABLE — reg_usb_pad_enable
  [11] USB_PAD_ENABLE_OVERRIDE — reg_usb_pad_enable_override
  [10] USB_PULLUP_VALUE — reg_usb_pullup_value
  [9] USB_DM_PULLDOWN — reg_usb_dm_pulldown
  [8] USB_DM_PULLUP — reg_usb_dm_pullup
  [7] USB_DP_PULLDOWN — reg_usb_dp_pulldown
  [6] USB_DP_PULLUP — reg_usb_dp_pullup
  [5] USB_PAD_PULL_OVERRIDE — reg_usb_pad_pull_override
  [4] USB_VREF_OVERRIDE — reg_usb_vref_override
  [3:2] USB_VREFL — reg_usb_vrefl
  [1:0] USB_VREFH — reg_usb_vrefh
0x124 RTC_TOUCH_TIMEOUT_CTRL reset 0x7FFFFF — configure touch controller
  [22] TOUCH_TIMEOUT_EN — enable touch timerout
  [21:0] TOUCH_TIMEOUT_NUM — configure touch timerout time
0x128 RTC_SLP_REJECT_CAUSE ro — get reject casue
  [17:0] REJECT_CAUSE — sleep reject cause
0x12C RTC_OPTION1 — rtc common configure
  [0] FORCE_DOWNLOAD_BOOT — force chip entry download boot by sw
0x130 RTC_SLP_WAKEUP_CAUSE ro — get wakeup cause
  [16:0] WAKEUP_CAUSE — sleep wakeup cause
0x134 RTC_ULP_CP_TIMER_1 reset 0xC800 — configure ulp sleep time
  [31:8] ULP_CP_TIMER_SLP_CYCLE — sleep cycles for ULP-coprocessor timer
0x138 INT_ENA_RTC_W1TS wo — oneset rtc interrupt
  [20] RTC_TOUCH_APPROACH_LOOP_DONE_INT_ENA_W1TS — enbale touch approach_loop done interrupt
  [19] RTC_GLITCH_DET_INT_ENA_W1TS — enbale gitch det interrupt
  [18] RTC_TOUCH_TIMEOUT_INT_ENA_W1TS — enable touch timeout interrupt
  [17] RTC_COCPU_TRAP_INT_ENA_W1TS — enable cocpu trap interrupt
  [16] RTC_XTAL32K_DEAD_INT_ENA_W1TS — enable xtal32k_dead interrupt
  [15] RTC_SWD_INT_ENA_W1TS — enable super watch dog interrupt
  [14] RTC_SARADC2_INT_ENA_W1TS — enable saradc2 interrupt
  [13] RTC_COCPU_INT_ENA_W1TS — enable riscV cocpu interrupt
  [12] RTC_TSENS_INT_ENA_W1TS — enable tsens interrupt
  [11] RTC_SARADC1_INT_ENA_W1TS — enable saradc1 interrupt
  [10] RTC_MAIN_TIMER_INT_ENA_W1TS — enable RTC main timer interrupt
  [9] RTC_BROWN_OUT_INT_ENA_W1TS — enable brown out interrupt
  [8] RTC_TOUCH_INACTIVE_INT_ENA_W1TS — enable touch inactive interrupt
  [7] RTC_TOUCH_ACTIVE_INT_ENA_W1TS — enable touch active interrupt
  [6] RTC_TOUCH_DONE_INT_ENA_W1TS — enable touch done interrupt
  [5] RTC_ULP_CP_INT_ENA_W1TS — enable ULP-coprocessor interrupt
  [4] RTC_TOUCH_SCAN_DONE_INT_ENA_W1TS — enable touch scan done interrupt
  [3] RTC_WDT_INT_ENA_W1TS — enable RTC WDT interrupt
  [2] SDIO_IDLE_INT_ENA_W1TS — enable SDIO idle interrupt
  [1] SLP_REJECT_INT_ENA_W1TS — enable sleep reject interrupt
  [0] SLP_WAKEUP_INT_ENA_W1TS — enable sleep wakeup interrupt
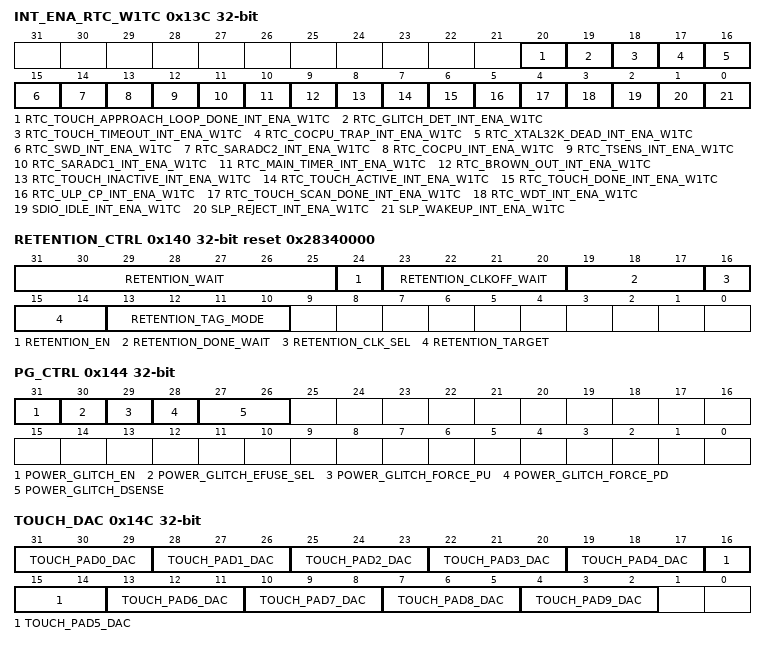
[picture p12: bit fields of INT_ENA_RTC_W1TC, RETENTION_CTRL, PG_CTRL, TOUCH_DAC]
0x13C INT_ENA_RTC_W1TC wo — oneset clr rtc interrupt enable
  [20] RTC_TOUCH_APPROACH_LOOP_DONE_INT_ENA_W1TC — enbale touch approach_loop done interrupt
  [19] RTC_GLITCH_DET_INT_ENA_W1TC — enbale gitch det interrupt
  [18] RTC_TOUCH_TIMEOUT_INT_ENA_W1TC — enable touch timeout interrupt
  [17] RTC_COCPU_TRAP_INT_ENA_W1TC — enable cocpu trap interrupt
  [16] RTC_XTAL32K_DEAD_INT_ENA_W1TC — enable xtal32k_dead interrupt
  [15] RTC_SWD_INT_ENA_W1TC — enable super watch dog interrupt
  [14] RTC_SARADC2_INT_ENA_W1TC — enable saradc2 interrupt
  [13] RTC_COCPU_INT_ENA_W1TC — enable riscV cocpu interrupt
  [12] RTC_TSENS_INT_ENA_W1TC — enable tsens interrupt
  [11] RTC_SARADC1_INT_ENA_W1TC — enable saradc1 interrupt
  [10] RTC_MAIN_TIMER_INT_ENA_W1TC — enable RTC main timer interrupt
  [9] RTC_BROWN_OUT_INT_ENA_W1TC — enable brown out interrupt
  [8] RTC_TOUCH_INACTIVE_INT_ENA_W1TC — enable touch inactive interrupt
  [7] RTC_TOUCH_ACTIVE_INT_ENA_W1TC — enable touch active interrupt
  [6] RTC_TOUCH_DONE_INT_ENA_W1TC — enable touch done interrupt
  [5] RTC_ULP_CP_INT_ENA_W1TC — enable ULP-coprocessor interrupt
  [4] RTC_TOUCH_SCAN_DONE_INT_ENA_W1TC — enable touch scan done interrupt
  [3] RTC_WDT_INT_ENA_W1TC — enable RTC WDT interrupt
  [2] SDIO_IDLE_INT_ENA_W1TC — enable SDIO idle interrupt
  [1] SLP_REJECT_INT_ENA_W1TC — enable sleep reject interrupt
  [0] SLP_WAKEUP_INT_ENA_W1TC — enable sleep wakeup interrupt
0x140 RETENTION_CTRL reset 0x28340000 — configure retention
  [31:25] RETENTION_WAIT — wait cycles for rention operation
  [24] RETENTION_EN — enable retention
  [23:20] RETENTION_CLKOFF_WAIT — wait clk off cycle
  [19:17] RETENTION_DONE_WAIT — wait retention done cycle
  [16] RETENTION_CLK_SEL — No public
  [15:14] RETENTION_TARGET — congfigure retention target cpu and/or tag
  [13:10] RETENTION_TAG_MODE — No public
0x144 PG_CTRL — configure power glitch
  [31] POWER_GLITCH_EN — enable power glitch
  [30] POWER_GLITCH_EFUSE_SEL — select use analog fib signal
  [29] POWER_GLITCH_FORCE_PU — force power glitch enable
  [28] POWER_GLITCH_FORCE_PD — force power glitch disable
  [27:26] POWER_GLITCH_DSENSE — GLITCH_DSENSE
0x148 RTC_FIB_SEL reset 0x7 — No public
  [2:0] RTC_FIB_SEL
0x14C TOUCH_DAC — configure touch dac
  [31-3n:29-3n] TOUCH_PAD{n}_DAC (n=0..9) — configure touch pad dac{n}
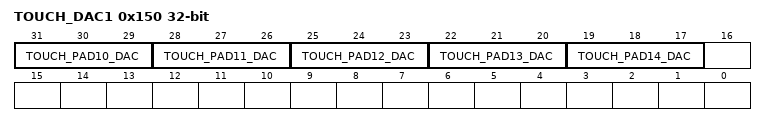
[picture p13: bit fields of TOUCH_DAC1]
0x150 TOUCH_DAC1 — configure touch dac
  [61-3n:59-3n] TOUCH_PAD{n}_DAC (n=10..14) — configure touch pad dac{n}
0x154 RTC_COCPU_DISABLE — configure ulp diable
  [31] DISABLE_RTC_CPU
0x1FC DATE reset 0x2101271 — version register
  [27:0] DATE
